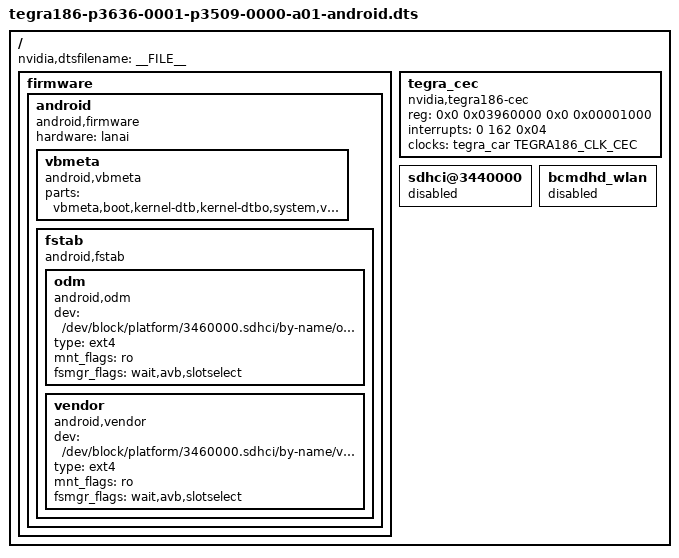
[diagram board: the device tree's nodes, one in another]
#include "tegra186-p3636-0001-p3509-0000-a01.dts"

/ {
	nvidia,dtsfilename = __FILE__;

	firmware {
		android {
			compatible = "android,firmware";
			hardware = "lanai";
			vbmeta {
				compatible = "android,vbmeta";
				parts = "vbmeta,boot,kernel-dtb,kernel-dtbo,system,vendor,recovery";
			};
			fstab {
				compatible = "android,fstab";
				odm {
					compatible = "android,odm";
					dev = "/dev/block/platform/3460000.sdhci/by-name/odm";
					type = "ext4";
					mnt_flags = "ro";
					fsmgr_flags = "wait,avb,slotselect";
				};
				vendor {
					compatible = "android,vendor";
					dev = "/dev/block/platform/3460000.sdhci/by-name/vendor";
					type = "ext4";
					mnt_flags = "ro";
					fsmgr_flags = "wait,avb,slotselect";
				};
			};
		};
	};

	tegra_cec {
		status = "okay";
		compatible = "nvidia,tegra186-cec";
		reg = <0x0 0x03960000 0x0 0x00001000>;
		interrupts = <0 162 0x04>;
		clocks = <&tegra_car TEGRA186_CLK_CEC>;
		clock-names = "cec";
	};

	sdhci@3440000 {
		status = "disabled";
	};

	bcmdhd_wlan {
		status = "disabled";
	};
};
